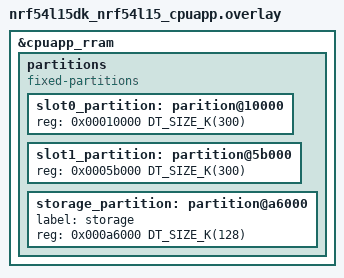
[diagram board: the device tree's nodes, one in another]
// Copyright 2025 MicroEJ Corp. All rights reserved.
// Use of this source code is governed by a BSD-style license that can be found with this software.

/* Increase storage_partition to 128kB to pass the test suite */
/delete-node/ &slot0_partition;
/delete-node/ &slot1_partition;
/delete-node/ &slot0_ns_partition;
/delete-node/ &slot1_ns_partition;
/delete-node/ &storage_partition;

&cpuapp_rram {
	partitions {
		compatible = "fixed-partitions";
		#address-cells = <1>;
		#size-cells = <1>;

		slot0_partition: parition@10000 {
			reg = <0x00010000 DT_SIZE_K(300)>;
		};
		slot1_partition: partition@5b000 {
			reg = <0x0005b000 DT_SIZE_K(300)>;
		};

		storage_partition: partition@a6000 {
			label = "storage";
			reg = <0x000a6000 DT_SIZE_K(128)>;
		};
	};
};
